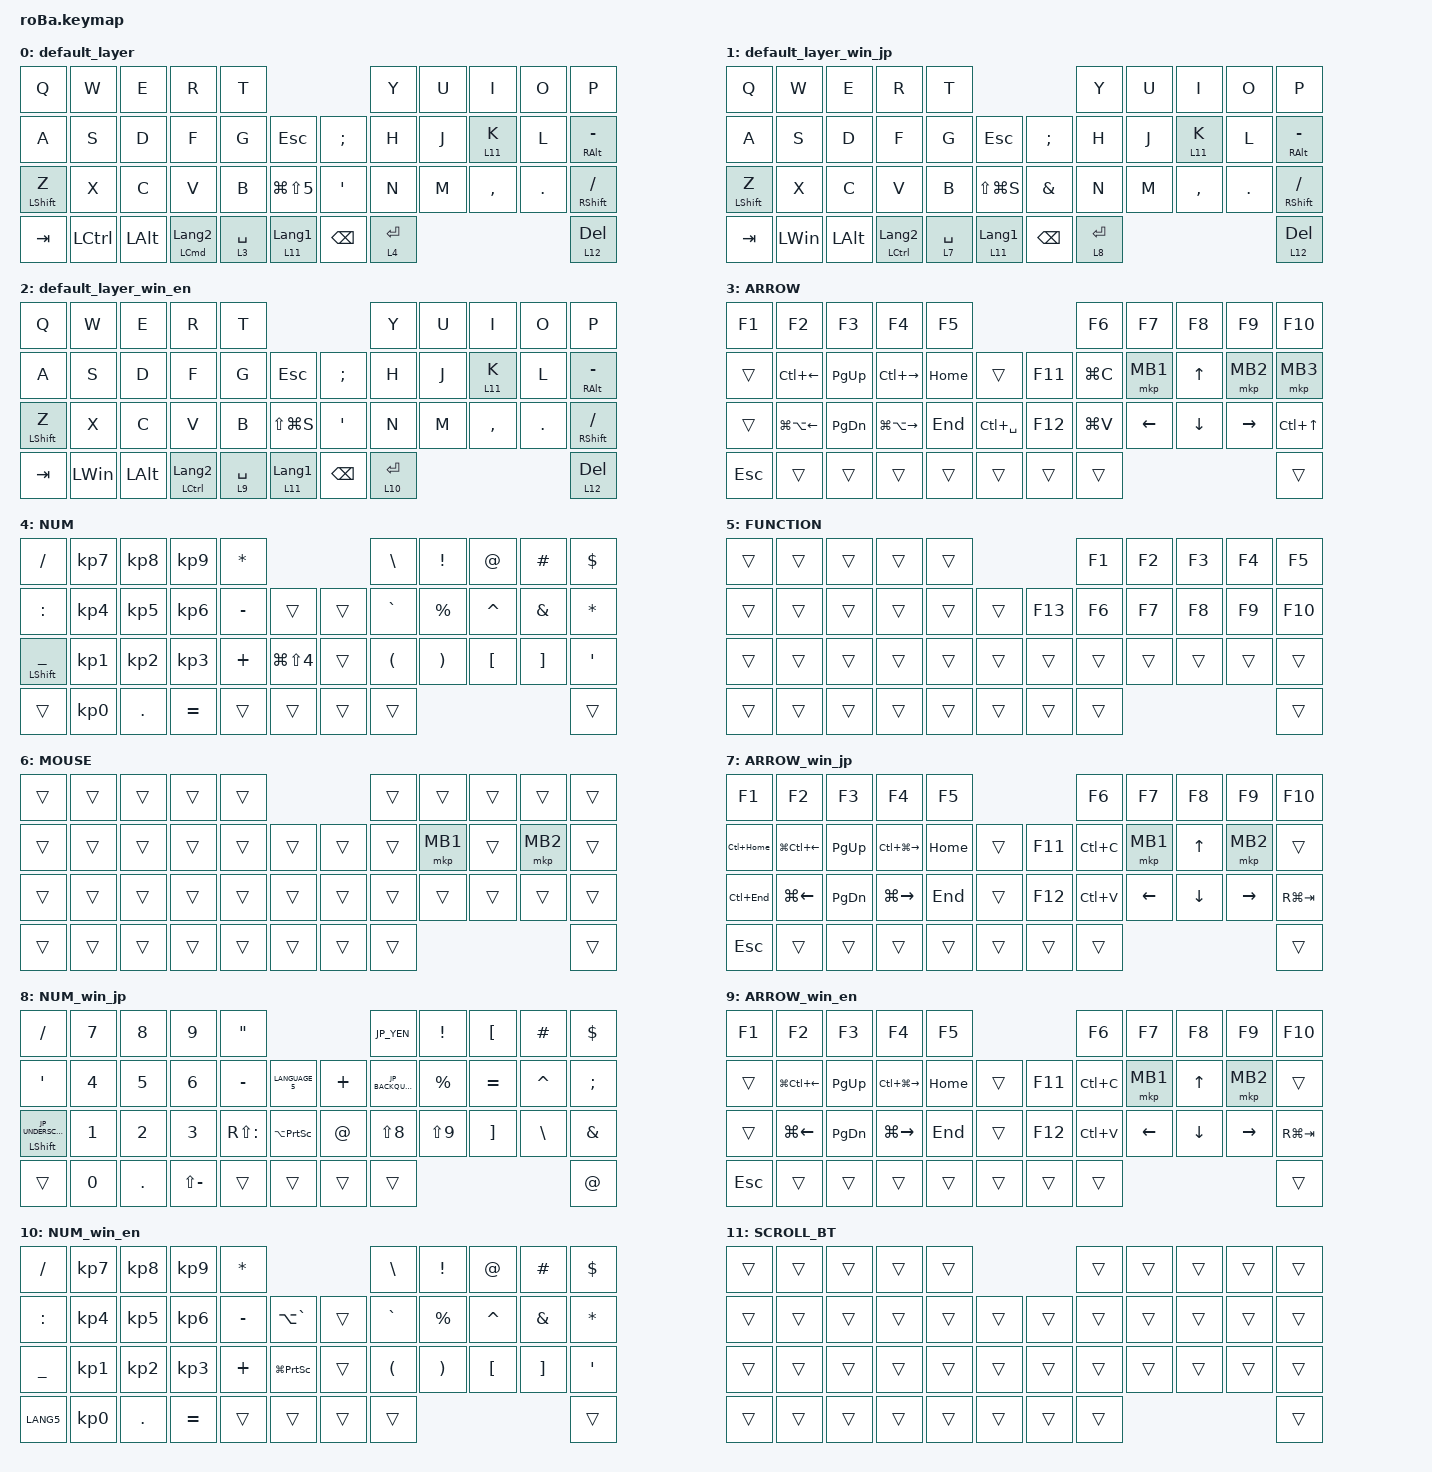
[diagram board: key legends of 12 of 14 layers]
#include <input/processors.dtsi>
#include <behaviors.dtsi>
#include <dt-bindings/zmk/bt.h>
#include <dt-bindings/zmk/keys.h>
#include <dt-bindings/zmk/pointing.h>

#define ZMK_POINTING_DEFAULT_SCRL_VAL 80
#define JP_YEN          0x89
#define JP_TILDE    　　LS(JP_CARET)
#define JP_BACKQUOTE    LEFT_BRACE
#define JP_UNDERSCORE   LS(0x87)

&mt {
    flavor = "balanced";
    quick-tap-ms = <0>;
};

&trackball {
    scroll-layers = <11>;
    automouse-layer = <6>;

    // arrows {
    //     layers = <3>;
    //     bindings =
    //         <&kp RIGHT_ARROW>,
    //         <&kp LEFT_ARROW>,
    //         <&kp UP_ARROW>,
    //         <&kp DOWN_ARROW>;
    //     tick = <10>;
    //     wait-ms = <5>;
    //     tap-ms = <5>;
    // };
};

/ {
    trackball_listener {
        compatible = "zmk,input-listener";
        device = <&trackball>;
        input-processors = <&zip_temp_layer 6 500>; // 6がAMLレイヤー、500が戻る時間（0.5秒）
    };
};

/ {
    combos {
        compatible = "zmk,combos";

        tab {
            bindings = <&kp TAB>;
            key-positions = <11 12>;
        };

        shift_tab {
            bindings = <&kp LS(TAB)>;
            key-positions = <12 13>;
        };

        LeftClick {
            bindings = <&mkp MB2>;
            key-positions = <20 19>;
        };

        RightClick {
            bindings = <&mkp MB1>;
            key-positions = <18 19>;
        };

        Escape {
            bindings = <&kp ESCAPE>;
            key-positions = <1 0>;
        };

        at_mark {
            bindings = <&kp LEFT_BRACKET>;
            key-positions = <6 7>;
            layers = <1>;
        };
    };

    macros {
        to_layer_0: to_layer_0 {
            compatible = "zmk,behavior-macro-one-param";
            #binding-cells = <1>;
            bindings = <&to 0 &macro_param_1to1>;
            label = "TO_LAYER_0";
        };

        change_windows_jp: change_windows_jp {
            compatible = "zmk,behavior-macro";
            #binding-cells = <0>;
            bindings = <&bt BT_SEL 4 &to 1>;
            label = "CHANGE_WINDOWS_JP";
        };

        change_mac: new_macro {
            compatible = "zmk,behavior-macro";
            #binding-cells = <0>;
            bindings = <&bt BT_SEL 0 &to 0>;
            label = "NEW_MACRO";
        };

        change_windows_en_private: change_win_en {
            compatible = "zmk,behavior-macro";
            #binding-cells = <0>;
            bindings = <&bt BT_SEL 1 &to 2>;
            label = "CHANGE_WIN_EN";
        };

        chang_win_work: chang_win_work {
            compatible = "zmk,behavior-macro";
            #binding-cells = <0>;
            bindings = <&bt BT_SEL 3 &to 2>;
            label = "CHANG_WIN_WORK";
        };

        change_iPad: change_iPad {
            compatible = "zmk,behavior-macro";
            #binding-cells = <0>;
            bindings = <&bt BT_SEL 2 &to 0>;
            label = "CHANGE_IPAD";
        };

        excel_text_paste: excel_text_paste {
            compatible = "zmk,behavior-macro";
            #binding-cells = <0>;
            bindings = <&kp LEFT_ALT &kp H &kp V &kp T>;
            label = "EXCEL_TEXT_PASTE";
        };
    };

    behaviors {
        lt_to_layer_0: lt_to_layer_0 {
            compatible = "zmk,behavior-hold-tap";
            label = "LAYER_TAP_TO_0";
            bindings = <&mo>, <&to_layer_0>;

            #binding-cells = <2>;
            tapping-term-ms = <200>;
        };

        encoder_msc_down_up: encoder_msc_down_up {
            compatible = "zmk,behavior-sensor-rotate";
            label = "ENCODER_MSC_DOWN_UP";
            #sensor-binding-cells = <0>;
            bindings = <&msc SCRL_UP>, <&msc SCRL_DOWN>;

            // 追加: スクロールのタップ時間を設定 (20ms)

            tap-ms = <20>;
        };
    };

    keymap {
        compatible = "zmk,keymap";

        default_layer {
            bindings = <
&kp Q             &kp W             &kp E         &kp R                &kp T                                                 &kp Y        &kp U  &kp I      &kp O    &kp P
&kp A             &kp S             &kp D         &kp F                &kp G        &kp ESCAPE             &kp SEMICOLON     &kp H        &kp J  &lt 11 K   &kp L    &mt RIGHT_ALT MINUS
&mt LEFT_SHIFT Z  &kp X             &kp C         &kp V                &kp B        &kp LG(LS(N5))         &kp SINGLE_QUOTE  &kp N        &kp M  &kp COMMA  &kp DOT  &mt RIGHT_SHIFT SLASH
&kp TAB           &kp LEFT_CONTROL  &kp LEFT_ALT  &mt LCMD LANGUAGE_2  &lt 3 SPACE  &lt 11 LANGUAGE_1      &kp BACKSPACE     &lt 4 ENTER                             &lt 12 DELETE
            >;

            sensor-bindings = <&encoder_msc_down_up>;
        };

        default_layer_win_jp {
            bindings = <
&kp Q             &kp W         &kp E         &kp R                 &kp T                                              &kp Y        &kp U  &kp I      &kp O    &kp P
&kp A             &kp S         &kp D         &kp F                 &kp G        &kp ESCAPE             &kp SEMICOLON  &kp H        &kp J  &lt 11 K   &kp L    &mt RIGHT_ALT MINUS
&mt LEFT_SHIFT Z  &kp X         &kp C         &kp V                 &kp B        &kp LS(LG(S))          &kp AMPERSAND  &kp N        &kp M  &kp COMMA  &kp DOT  &mt RIGHT_SHIFT SLASH
&kp TAB           &kp LEFT_WIN  &kp LEFT_ALT  &mt LCTRL LANGUAGE_2  &lt 7 SPACE  &lt 11 LANGUAGE_1      &kp BACKSPACE  &lt 8 ENTER                             &lt 12 DELETE
            >;

            sensor-bindings = <&encoder_msc_down_up>;
        };

        default_layer_win_en {
            bindings = <
&kp Q             &kp W         &kp E         &kp R                 &kp T                                                 &kp Y         &kp U  &kp I      &kp O    &kp P
&kp A             &kp S         &kp D         &kp F                 &kp G        &kp ESCAPE             &kp SEMICOLON     &kp H         &kp J  &lt 11 K   &kp L    &mt RIGHT_ALT MINUS
&mt LEFT_SHIFT Z  &kp X         &kp C         &kp V                 &kp B        &kp LS(LG(S))          &kp SINGLE_QUOTE  &kp N         &kp M  &kp COMMA  &kp DOT  &mt RIGHT_SHIFT SLASH
&kp TAB           &kp LEFT_WIN  &kp LEFT_ALT  &mt LCTRL LANGUAGE_2  &lt 9 SPACE  &lt 11 LANGUAGE_1      &kp BACKSPACE     &lt 10 ENTER                             &lt 12 DELETE
            >;

            sensor-bindings = <&encoder_msc_down_up>;
        };

        ARROW {
            bindings = <
&kp F1      &kp F2              &kp F3         &kp F4                   &kp F5                                &kp F6     &kp F7    &kp F8        &kp F9     &kp F10
&trans      &kp LC(LEFT_ARROW)  &kp PAGE_UP    &kp LC(RIGHT_ARROW)      &kp HOME  &trans             &kp F11  &kp LG(C)  &mkp MB1  &kp UP_ARROW  &mkp MB2   &mkp MB3
&trans      &kp LG(LA(LEFT))    &kp PAGE_DOWN  &kp LG(LA(RIGHT_ARROW))  &kp END   &kp LC(SPACE)      &kp F12  &kp LG(V)  &kp LEFT  &kp DOWN      &kp RIGHT  &kp LC(UP_ARROW)
&kp ESCAPE  &trans              &trans         &trans                   &trans    &trans             &trans   &trans                                        &trans
            >;

            sensor-bindings = <&inc_dec_kp DOWN UP>;
        };

        NUM {
            bindings = <
&kp SLASH                  &kp KP_NUMBER_7  &kp KP_NUMBER_8  &kp KP_NUMBER_9  &kp ASTERISK                                    &kp BSLH              &kp EXCLAMATION        &kp AT_SIGN       &kp HASH           &kp DOLLAR
&kp COLON                  &kp KP_NUMBER_4  &kp KP_NUMBER_5  &kp KP_NUMBER_6  &kp MINUS     &trans                    &trans  &kp GRAVE             &kp PERCENT            &kp CARET         &kp AMPERSAND      &kp ASTERISK
&mt LEFT_SHIFT UNDERSCORE  &kp KP_NUMBER_1  &kp KP_NUMBER_2  &kp KP_NUMBER_3  &kp PLUS      &kp LG(LS(NUMBER_4))      &trans  &kp LEFT_PARENTHESIS  &kp RIGHT_PARENTHESIS  &kp LEFT_BRACKET  &kp RIGHT_BRACKET  &kp SINGLE_QUOTE
&trans                     &kp KP_N0        &kp PERIOD       &kp EQUAL        &trans        &trans                    &trans  &trans                                                                            &trans
            >;

            sensor-bindings = <&inc_dec_kp C_VOLUME_DOWN C_VOLUME_UP>;
        };

        FUNCTION {
            bindings = <
&trans  &trans  &trans  &trans  &trans                       &kp F1  &kp F2  &kp F3  &kp F4  &kp F5
&trans  &trans  &trans  &trans  &trans  &trans      &kp F13  &kp F6  &kp F7  &kp F8  &kp F9  &kp F10
&trans  &trans  &trans  &trans  &trans  &trans      &trans   &trans  &trans  &trans  &trans  &trans
&trans  &trans  &trans  &trans  &trans  &trans      &trans   &trans                          &trans
            >;
        };

        MOUSE {
            bindings = <
&trans  &trans  &trans  &trans  &trans                      &trans  &trans    &trans  &trans    &trans
&trans  &trans  &trans  &trans  &trans  &trans      &trans  &trans  &mkp MB1  &trans  &mkp MB2  &trans
&trans  &trans  &trans  &trans  &trans  &trans      &trans  &trans  &trans    &trans  &trans    &trans
&trans  &trans  &trans  &trans  &trans  &trans      &trans  &trans                              &trans
            >;
        };

        ARROW_win_jp {
            bindings = <
&kp F1        &kp F2                  &kp F3         &kp F4                   &kp F5                         &kp F6     &kp F7    &kp F8        &kp F9     &kp F10
&kp LC(HOME)  &kp LG(LC(LEFT_ARROW))  &kp PAGE_UP    &kp LC(LG(RIGHT_ARROW))  &kp HOME  &trans      &kp F11  &kp LC(C)  &mkp MB1  &kp UP_ARROW  &mkp MB2   &trans
&kp LC(END)   &kp LG(LEFT)            &kp PAGE_DOWN  &kp LG(RIGHT_ARROW)      &kp END   &trans      &kp F12  &kp LC(V)  &kp LEFT  &kp DOWN      &kp RIGHT  &kp RG(TAB)
&kp ESCAPE    &trans                  &trans         &trans                   &trans    &trans      &trans   &trans                                        &trans
            >;

            sensor-bindings = <&inc_dec_kp DOWN UP>;
        };

        NUM_win_jp {
            bindings = <
&kp SLASH                     &kp N7        &kp N8        &kp N9         &kp DOUBLE_QUOTES                                     &kp JP_YEN        &kp EXCLAMATION  &kp LEFT_BRACKET   &kp HASH       &kp DOLLAR
&kp SQT                       &kp NUMBER_4  &kp N5        &kp NUMBER_6   &kp MINUS          &kp LANGUAGE_5           &kp PLUS  &kp JP_BACKQUOTE  &kp PERCENT      &kp EQUAL          &kp CARET      &kp SEMICOLON
&mt LEFT_SHIFT JP_UNDERSCORE  &kp N1        &kp NUMBER_2  &kp NUMBER_3   &kp RS(COLON)      &kp LA(PRINTSCREEN)      &kp AT    &kp LS(N8)        &kp LS(N9)       &kp RIGHT_BRACKET  &kp BACKSLASH  &kp AMPERSAND
&trans                        &kp N0        &kp PERIOD    &kp LS(MINUS)  &trans             &trans                   &trans    &trans                                                               &kp AT
            >;

            sensor-bindings = <&inc_dec_kp C_VOLUME_DOWN C_VOL_UP>;
        };

        ARROW_win_en {
            bindings = <
&kp F1      &kp F2                  &kp F3         &kp F4                   &kp F5                         &kp F6     &kp F7    &kp F8        &kp F9     &kp F10
&trans      &kp LG(LC(LEFT_ARROW))  &kp PAGE_UP    &kp LC(LG(RIGHT_ARROW))  &kp HOME  &trans      &kp F11  &kp LC(C)  &mkp MB1  &kp UP_ARROW  &mkp MB2   &trans
&trans      &kp LG(LEFT)            &kp PAGE_DOWN  &kp LG(RIGHT_ARROW)      &kp END   &trans      &kp F12  &kp LC(V)  &kp LEFT  &kp DOWN      &kp RIGHT  &kp RG(TAB)
&kp ESCAPE  &trans                  &trans         &trans                   &trans    &trans      &trans   &trans                                        &trans
            >;

            sensor-bindings = <&inc_dec_kp DOWN UP>;
        };

        NUM_win_en {
            bindings = <
&kp SLASH       &kp KP_NUMBER_7  &kp KP_NUMBER_8  &kp KP_NUMBER_9  &kp ASTERISK                                   &kp BSLH              &kp EXCLAMATION        &kp AT_SIGN       &kp HASH           &kp DOLLAR
&kp COLON       &kp KP_NUMBER_4  &kp KP_NUMBER_5  &kp KP_NUMBER_6  &kp MINUS     &kp LA(GRAVE)            &trans  &kp GRAVE             &kp PERCENT            &kp CARET         &kp AMPERSAND      &kp ASTERISK
&kp UNDERSCORE  &kp KP_NUMBER_1  &kp KP_NUMBER_2  &kp KP_NUMBER_3  &kp PLUS      &kp LG(PRINTSCREEN)      &trans  &kp LEFT_PARENTHESIS  &kp RIGHT_PARENTHESIS  &kp LEFT_BRACKET  &kp RIGHT_BRACKET  &kp SINGLE_QUOTE
&kp LANG5       &kp KP_N0        &kp PERIOD       &kp EQUAL        &trans        &trans                   &trans  &trans                                                                            &trans
            >;

            sensor-bindings = <&inc_dec_kp C_VOLUME_DOWN C_VOLUME_UP>;
        };

        SCROLL_BT {
            bindings = <
&trans  &trans  &trans  &trans  &trans                      &trans  &trans  &trans  &trans  &trans
&trans  &trans  &trans  &trans  &trans  &trans      &trans  &trans  &trans  &trans  &trans  &trans
&trans  &trans  &trans  &trans  &trans  &trans      &trans  &trans  &trans  &trans  &trans  &trans
&trans  &trans  &trans  &trans  &trans  &trans      &trans  &trans                          &trans
            >;
        };

        BT {
            bindings = <
&trans  &trans  &trans  &trans  &trans                          &trans       &trans                      &trans        &trans           &bt BT_SEL 4
&trans  &trans  &trans  &trans  &trans  &trans      &trans      &change_mac  &change_windows_en_private  &change_iPad  &chang_win_work  &change_windows_jp
&trans  &trans  &trans  &trans  &trans  &trans      &bt BT_CLR  &trans       &trans                      &trans        &trans           &trans
&trans  &trans  &trans  &trans  &trans  &trans      &trans      &trans                                                                  &trans
            >;
        };

        Excel {
            bindings = <
&trans  &trans  &trans  &trans  &trans                                  &trans             &trans  &trans  &trans  &trans
&trans  &trans  &trans  &trans  &trans  &trans      &kp LC(SEMICOLON)   &trans             &trans  &trans  &trans  &trans
&trans  &trans  &trans  &trans  &trans  &trans      &kp LC(APOSTROPHE)  &excel_text_paste  &trans  &trans  &trans  &trans
&trans  &trans  &trans  &trans  &trans  &trans      &trans              &trans                                     &trans
            >;
        };
    };
};
